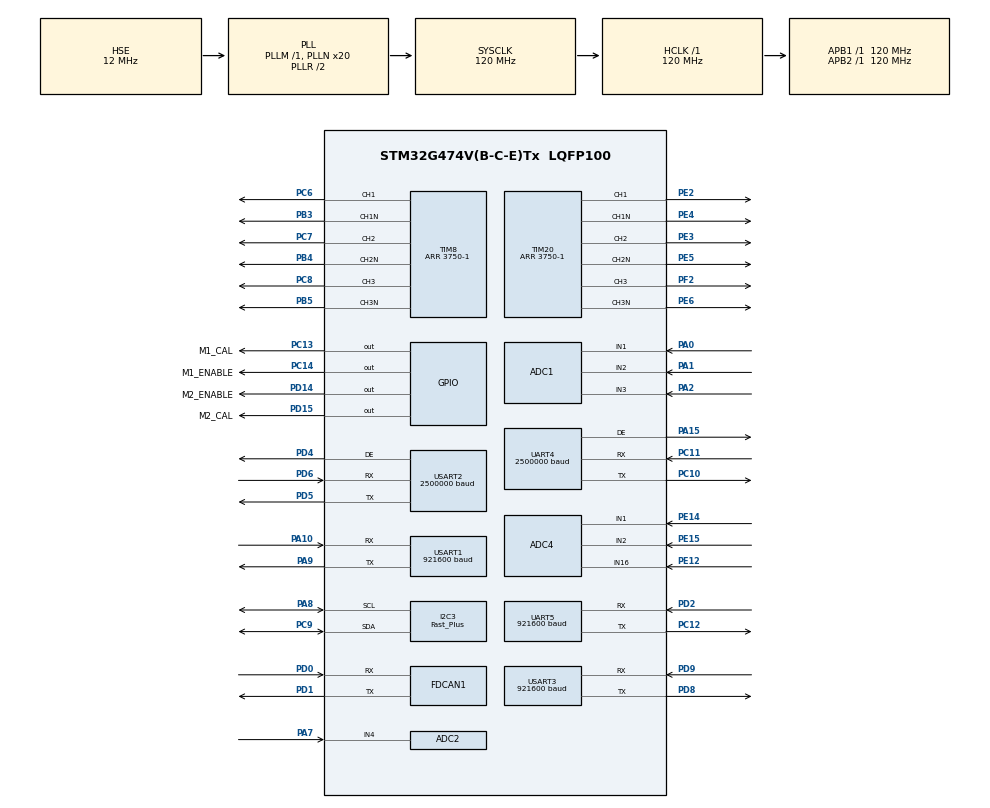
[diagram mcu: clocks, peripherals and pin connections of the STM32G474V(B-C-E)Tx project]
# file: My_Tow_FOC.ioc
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ADC1.ClockPrescaler=ADC_CLOCK_SYNC_PCLK_DIV4
ADC1.EnableInjectedConversion=ENABLE
ADC1.EnableRegularConversion=DISABLE
ADC1.ExternalTrigInjecConv=ADC_EXTERNALTRIGINJEC_T20_TRGO2
ADC1.InjNumberOfConversion=3
ADC1.InjectedChannel-4\#ChannelInjectedConversion=ADC_CHANNEL_1
ADC1.InjectedChannel-5\#ChannelInjectedConversion=ADC_CHANNEL_2
ADC1.InjectedChannel-6\#ChannelInjectedConversion=ADC_CHANNEL_3
ADC1.InjectedOffsetNumber-4\#ChannelInjectedConversion=ADC_OFFSET_NONE
ADC1.InjectedOffsetNumber-5\#ChannelInjectedConversion=ADC_OFFSET_NONE
ADC1.InjectedOffsetNumber-6\#ChannelInjectedConversion=ADC_OFFSET_NONE
ADC1.InjectedRank-4\#ChannelInjectedConversion=1
ADC1.InjectedRank-5\#ChannelInjectedConversion=2
ADC1.InjectedRank-6\#ChannelInjectedConversion=3
ADC1.InjectedSamplingTime-4\#ChannelInjectedConversion=ADC_SAMPLETIME_12CYCLES_5
ADC1.InjectedSamplingTime-5\#ChannelInjectedConversion=ADC_SAMPLETIME_12CYCLES_5
ADC1.InjectedSamplingTime-6\#ChannelInjectedConversion=ADC_SAMPLETIME_12CYCLES_5
ADC1.Rank1_Channel=ADC_CHANNEL_1
ADC1.Rank2_Channel=ADC_CHANNEL_2
ADC1.Rank3_Channel=ADC_CHANNEL_3
ADC1.master=1
ADC2.Channel-2\#ChannelRegularConversion=ADC_CHANNEL_4
ADC2.ClockPrescaler=ADC_CLOCK_SYNC_PCLK_DIV4
ADC2.ContinuousConvMode=ENABLE
ADC2.NbrOfConversionFlag=1
ADC2.OffsetNumber-2\#ChannelRegularConversion=ADC_OFFSET_NONE
ADC2.Rank-2\#ChannelRegularConversion=1
ADC2.SamplingTime-2\#ChannelRegularConversion=ADC_SAMPLETIME_12CYCLES_5
ADC4.ClockPrescaler=ADC_CLOCK_SYNC_PCLK_DIV4
ADC4.EnableInjectedConversion=ENABLE
ADC4.EnableRegularConversion=DISABLE
ADC4.ExternalTrigInjecConv=ADC_EXTERNALTRIGINJEC_T8_TRGO2
ADC4.InjNumberOfConversion=3
ADC4.InjectedChannel-2\#ChannelInjectedConversion=ADC_CHANNEL_2
ADC4.InjectedChannel-3\#ChannelInjectedConversion=ADC_CHANNEL_1
ADC4.InjectedChannel-4\#ChannelInjectedConversion=ADC_CHANNEL_16
ADC4.InjectedOffsetNumber-2\#ChannelInjectedConversion=ADC_OFFSET_NONE
ADC4.InjectedOffsetNumber-3\#ChannelInjectedConversion=ADC_OFFSET_NONE
ADC4.InjectedOffsetNumber-4\#ChannelInjectedConversion=ADC_OFFSET_NONE
ADC4.InjectedRank-2\#ChannelInjectedConversion=1
ADC4.InjectedRank-3\#ChannelInjectedConversion=2
ADC4.InjectedRank-4\#ChannelInjectedConversion=3
ADC4.InjectedSamplingTime-2\#ChannelInjectedConversion=ADC_SAMPLETIME_12CYCLES_5
ADC4.InjectedSamplingTime-3\#ChannelInjectedConversion=ADC_SAMPLETIME_12CYCLES_5
ADC4.InjectedSamplingTime-4\#ChannelInjectedConversion=ADC_SAMPLETIME_12CYCLES_5
ADC4.Rank1_Channel=ADC_CHANNEL_2
ADC4.Rank2_Channel=ADC_CHANNEL_1
ADC4.Rank3_Channel=ADC_CHANNEL_16
Dma.Request0=USART1_RX
Dma.Request1=USART1_TX
Dma.Request2=USART3_RX
Dma.Request3=USART3_TX
Dma.Request4=USART2_RX
Dma.Request5=USART2_TX
Dma.Request6=UART4_RX
Dma.Request7=UART4_TX
Dma.UART4_RX.6.Direction=DMA_PERIPH_TO_MEMORY
Dma.UART4_RX.6.EventEnable=DISABLE
Dma.UART4_RX.6.Instance=DMA1_Channel7
Dma.UART4_RX.6.MemDataAlignment=DMA_MDATAALIGN_BYTE
Dma.UART4_RX.6.MemInc=DMA_MINC_ENABLE
Dma.UART4_RX.6.Mode=DMA_NORMAL
Dma.UART4_RX.6.PeriphDataAlignment=DMA_PDATAALIGN_BYTE
Dma.UART4_RX.6.PeriphInc=DMA_PINC_DISABLE
Dma.UART4_RX.6.Polarity=HAL_DMAMUX_REQ_GEN_RISING
Dma.UART4_RX.6.Priority=DMA_PRIORITY_LOW
Dma.UART4_RX.6.RequestNumber=1
Dma.UART4_RX.6.SignalID=NONE
Dma.UART4_RX.6.SyncEnable=DISABLE
Dma.UART4_RX.6.SyncPolarity=HAL_DMAMUX_SYNC_NO_EVENT
Dma.UART4_RX.6.SyncRequestNumber=1
Dma.UART4_RX.6.SyncSignalID=NONE
Dma.UART4_TX.7.Direction=DMA_MEMORY_TO_PERIPH
Dma.UART4_TX.7.EventEnable=DISABLE
Dma.UART4_TX.7.Instance=DMA1_Channel8
Dma.UART4_TX.7.MemDataAlignment=DMA_MDATAALIGN_BYTE
Dma.UART4_TX.7.MemInc=DMA_MINC_ENABLE
Dma.UART4_TX.7.Mode=DMA_NORMAL
Dma.UART4_TX.7.PeriphDataAlignment=DMA_PDATAALIGN_BYTE
Dma.UART4_TX.7.PeriphInc=DMA_PINC_DISABLE
Dma.UART4_TX.7.Polarity=HAL_DMAMUX_REQ_GEN_RISING
Dma.UART4_TX.7.Priority=DMA_PRIORITY_LOW
Dma.UART4_TX.7.RequestNumber=1
Dma.UART4_TX.7.SignalID=NONE
Dma.UART4_TX.7.SyncEnable=DISABLE
Dma.UART4_TX.7.SyncPolarity=HAL_DMAMUX_SYNC_NO_EVENT
Dma.UART4_TX.7.SyncRequestNumber=1
Dma.UART4_TX.7.SyncSignalID=NONE
Dma.USART1_RX.0.Direction=DMA_PERIPH_TO_MEMORY
Dma.USART1_RX.0.EventEnable=DISABLE
Dma.USART1_RX.0.Instance=DMA1_Channel1
Dma.USART1_RX.0.MemDataAlignment=DMA_MDATAALIGN_BYTE
Dma.USART1_RX.0.MemInc=DMA_MINC_ENABLE
Dma.USART1_RX.0.Mode=DMA_NORMAL
Dma.USART1_RX.0.PeriphDataAlignment=DMA_PDATAALIGN_BYTE
Dma.USART1_RX.0.PeriphInc=DMA_PINC_DISABLE
Dma.USART1_RX.0.Polarity=HAL_DMAMUX_REQ_GEN_RISING
Dma.USART1_RX.0.Priority=DMA_PRIORITY_LOW
Dma.USART1_RX.0.RequestNumber=1
Dma.USART1_RX.0.SignalID=NONE
Dma.USART1_RX.0.SyncEnable=DISABLE
Dma.USART1_RX.0.SyncPolarity=HAL_DMAMUX_SYNC_NO_EVENT
Dma.USART1_RX.0.SyncRequestNumber=1
Dma.USART1_RX.0.SyncSignalID=NONE
Dma.USART1_TX.1.Direction=DMA_MEMORY_TO_PERIPH
Dma.USART1_TX.1.EventEnable=DISABLE
Dma.USART1_TX.1.Instance=DMA1_Channel2
Dma.USART1_TX.1.MemDataAlignment=DMA_MDATAALIGN_BYTE
Dma.USART1_TX.1.MemInc=DMA_MINC_ENABLE
Dma.USART1_TX.1.Mode=DMA_NORMAL
Dma.USART1_TX.1.PeriphDataAlignment=DMA_PDATAALIGN_BYTE
Dma.USART1_TX.1.PeriphInc=DMA_PINC_DISABLE
Dma.USART1_TX.1.Polarity=HAL_DMAMUX_REQ_GEN_RISING
Dma.USART1_TX.1.Priority=DMA_PRIORITY_LOW
Dma.USART1_TX.1.RequestNumber=1
Dma.USART1_TX.1.SignalID=NONE
Dma.USART1_TX.1.SyncEnable=DISABLE
Dma.USART1_TX.1.SyncPolarity=HAL_DMAMUX_SYNC_NO_EVENT
Dma.USART1_TX.1.SyncRequestNumber=1
Dma.USART1_TX.1.SyncSignalID=NONE
Dma.USART2_RX.4.Direction=DMA_PERIPH_TO_MEMORY
Dma.USART2_RX.4.EventEnable=DISABLE
Dma.USART2_RX.4.Instance=DMA1_Channel5
Dma.USART2_RX.4.MemDataAlignment=DMA_MDATAALIGN_BYTE
Dma.USART2_RX.4.MemInc=DMA_MINC_ENABLE
Dma.USART2_RX.4.Mode=DMA_NORMAL
Dma.USART2_RX.4.PeriphDataAlignment=DMA_PDATAALIGN_BYTE
Dma.USART2_RX.4.PeriphInc=DMA_PINC_DISABLE
Dma.USART2_RX.4.Polarity=HAL_DMAMUX_REQ_GEN_RISING
Dma.USART2_RX.4.Priority=DMA_PRIORITY_LOW
Dma.USART2_RX.4.RequestNumber=1
Dma.USART2_RX.4.SignalID=NONE
Dma.USART2_RX.4.SyncEnable=DISABLE
Dma.USART2_RX.4.SyncPolarity=HAL_DMAMUX_SYNC_NO_EVENT
Dma.USART2_RX.4.SyncRequestNumber=1
Dma.USART2_RX.4.SyncSignalID=NONE
Dma.USART2_TX.5.Direction=DMA_MEMORY_TO_PERIPH
Dma.USART2_TX.5.EventEnable=DISABLE
Dma.USART2_TX.5.Instance=DMA1_Channel6
Dma.USART2_TX.5.MemDataAlignment=DMA_MDATAALIGN_BYTE
Dma.USART2_TX.5.MemInc=DMA_MINC_ENABLE
Dma.USART2_TX.5.Mode=DMA_NORMAL
Dma.USART2_TX.5.PeriphDataAlignment=DMA_PDATAALIGN_BYTE
Dma.USART2_TX.5.PeriphInc=DMA_PINC_DISABLE
Dma.USART2_TX.5.Polarity=HAL_DMAMUX_REQ_GEN_RISING
Dma.USART2_TX.5.Priority=DMA_PRIORITY_LOW
Dma.USART2_TX.5.RequestNumber=1
Dma.USART2_TX.5.SignalID=NONE
Dma.USART2_TX.5.SyncEnable=DISABLE
Dma.USART2_TX.5.SyncPolarity=HAL_DMAMUX_SYNC_NO_EVENT
Dma.USART2_TX.5.SyncRequestNumber=1
Dma.USART2_TX.5.SyncSignalID=NONE
Dma.USART3_RX.2.Direction=DMA_PERIPH_TO_MEMORY
Dma.USART3_RX.2.EventEnable=DISABLE
Dma.USART3_RX.2.Instance=DMA1_Channel3
Dma.USART3_RX.2.MemDataAlignment=DMA_MDATAALIGN_BYTE
Dma.USART3_RX.2.MemInc=DMA_MINC_ENABLE
Dma.USART3_RX.2.Mode=DMA_NORMAL
Dma.USART3_RX.2.PeriphDataAlignment=DMA_PDATAALIGN_BYTE
Dma.USART3_RX.2.PeriphInc=DMA_PINC_DISABLE
Dma.USART3_RX.2.Polarity=HAL_DMAMUX_REQ_GEN_RISING
Dma.USART3_RX.2.Priority=DMA_PRIORITY_LOW
Dma.USART3_RX.2.RequestNumber=1
Dma.USART3_RX.2.SignalID=NONE
Dma.USART3_RX.2.SyncEnable=DISABLE
Dma.USART3_RX.2.SyncPolarity=HAL_DMAMUX_SYNC_NO_EVENT
Dma.USART3_RX.2.SyncRequestNumber=1
Dma.USART3_RX.2.SyncSignalID=NONE
Dma.USART3_TX.3.Direction=DMA_MEMORY_TO_PERIPH
Dma.USART3_TX.3.EventEnable=DISABLE
Dma.USART3_TX.3.Instance=DMA1_Channel4
Dma.USART3_TX.3.MemDataAlignment=DMA_MDATAALIGN_BYTE
Dma.USART3_TX.3.MemInc=DMA_MINC_ENABLE
Dma.USART3_TX.3.Mode=DMA_NORMAL
Dma.USART3_TX.3.PeriphDataAlignment=DMA_PDATAALIGN_BYTE
Dma.USART3_TX.3.PeriphInc=DMA_PINC_DISABLE
Dma.USART3_TX.3.Polarity=HAL_DMAMUX_REQ_GEN_RISING
Dma.USART3_TX.3.Priority=DMA_PRIORITY_LOW
Dma.USART3_TX.3.RequestNumber=1
Dma.USART3_TX.3.SignalID=NONE
Dma.USART3_TX.3.SyncEnable=DISABLE
Dma.USART3_TX.3.SyncPolarity=HAL_DMAMUX_SYNC_NO_EVENT
Dma.USART3_TX.3.SyncRequestNumber=1
Dma.USART3_TX.3.SyncSignalID=NONE
FDCAN1.CalculateBaudRateNominal=1000000
FDCAN1.CalculateTimeBitNominal=1000
FDCAN1.CalculateTimeQuantumNominal=50.0
FDCAN1.ClockDivider=FDCAN_CLOCK_DIV1
FDCAN1.NominalPrescaler=6
FDCAN1.NominalTimeSeg1=15
FDCAN1.NominalTimeSeg2=4
FREERTOS.Tasks01=defaultTask,24,128,StartDefaultTask,Default,NULL,Dynamic,NULL,NULL
FREERTOS.configTOTAL_HEAP_SIZE=80000
I2C3.I2C_Speed_Mode=I2C_Fast_Plus
I2C3.Timing=0x10820B1B
Mcu.Family=STM32G4
Mcu.Name=STM32G474V(B-C-E)Tx
Mcu.Package=LQFP100
NVIC.DMA1_Channel1_IRQn=true\:5\:0\:false\:false\:true\:true\:false\:true\:true
NVIC.DMA1_Channel2_IRQn=true\:5\:0\:false\:false\:true\:true\:false\:true\:true
NVIC.DMA1_Channel3_IRQn=true\:5\:0\:false\:false\:true\:true\:false\:true\:true
NVIC.DMA1_Channel4_IRQn=true\:5\:0\:false\:false\:true\:true\:false\:true\:true
NVIC.DMA1_Channel5_IRQn=true\:5\:0\:false\:false\:true\:true\:false\:true\:true
NVIC.DMA1_Channel6_IRQn=true\:5\:0\:false\:false\:true\:true\:false\:true\:true
NVIC.DMA1_Channel7_IRQn=true\:5\:0\:false\:false\:true\:true\:false\:true\:true
NVIC.DMA1_Channel8_IRQn=true\:5\:0\:false\:false\:true\:true\:false\:true\:true
NVIC.I2C3_ER_IRQn=true\:5\:0\:false\:false\:true\:true\:true\:true\:true
NVIC.I2C3_EV_IRQn=true\:5\:0\:false\:false\:true\:true\:true\:true\:true
NVIC.PriorityGroup=NVIC_PRIORITYGROUP_4
NVIC.TIM1_TRG_COM_TIM17_IRQn=true\:15\:0\:false\:false\:true\:false\:false\:true\:true
NVIC.TIM20_BRK_IRQn=true\:5\:0\:false\:false\:true\:true\:true\:true\:true
NVIC.TIM20_CC_IRQn=true\:5\:0\:false\:false\:true\:true\:true\:true\:true
NVIC.TIM20_TRG_COM_IRQn=true\:5\:0\:false\:false\:true\:true\:true\:true\:true
NVIC.TIM20_UP_IRQn=true\:5\:0\:false\:false\:true\:true\:true\:true\:true
NVIC.TIM8_BRK_IRQn=true\:5\:0\:false\:false\:true\:true\:true\:true\:true
NVIC.TIM8_CC_IRQn=true\:5\:0\:false\:false\:true\:true\:true\:true\:true
NVIC.TIM8_TRG_COM_IRQn=true\:5\:0\:false\:false\:true\:true\:true\:true\:true
NVIC.TIM8_UP_IRQn=true\:5\:0\:false\:false\:true\:true\:true\:true\:true
NVIC.TimeBase=TIM1_TRG_COM_TIM17_IRQn
NVIC.TimeBaseIP=TIM17
NVIC.UART4_IRQn=true\:5\:0\:false\:false\:true\:true\:true\:true\:true
NVIC.USART1_IRQn=true\:5\:0\:false\:false\:true\:true\:false\:true\:true
NVIC.USART2_IRQn=true\:5\:0\:false\:false\:true\:true\:true\:true\:true
NVIC.USART3_IRQn=true\:5\:0\:false\:false\:true\:true\:false\:true\:true
PA0.Mode=IN1-Single-Ended
PA0.Signal=ADC1_IN1
PA1.Mode=IN2-Single-Ended
PA1.Signal=ADC1_IN2
PA10.Mode=Asynchronous
PA10.Signal=USART1_RX
PA13.Mode=Serial_Wire
PA13.Signal=SYS_JTMS-SWDIO
PA14.Mode=Serial_Wire
PA14.Signal=SYS_JTCK-SWCLK
PA15.Mode=Hardware Flow Control (RS485)
PA15.Signal=UART4_DE
PA2.Mode=IN3-Single-Ended
PA2.Signal=ADC1_IN3
PA7.Mode=IN4-Single-Ended
PA7.Signal=ADC2_IN4
PA8.Mode=I2C
PA8.Signal=I2C3_SCL
PA9.Mode=Asynchronous
PA9.Signal=USART1_TX
PB3.Mode=PWM Generation1 CH1 CH1N
PB3.Signal=TIM8_CH1N
PB4.Mode=PWM Generation2 CH2 CH2N
PB4.Signal=TIM8_CH2N
PB5.Mode=PWM Generation3 CH3 CH3N
PB5.Signal=TIM8_CH3N
PC10.Mode=Asynchronous
PC10.Signal=UART4_TX
PC11.Mode=Asynchronous
PC11.Signal=UART4_RX
PC12.Mode=Asynchronous
PC12.Signal=UART5_TX
PC13.GPIO_Label=M1_CAL
PC13.GPIO_ModeDefaultOutputPP=GPIO_MODE_OUTPUT_PP
PC13.GPIO_PuPd=GPIO_PULLDOWN
PC13.GPIO_Speed=GPIO_SPEED_FREQ_LOW
PC13.PinState=GPIO_PIN_RESET
PC13.Signal=GPIO_Output
PC14-OSC32_IN.GPIO_Label=M1_ENABLE
PC14-OSC32_IN.GPIO_PuPd=GPIO_PULLUP
PC14-OSC32_IN.PinState=GPIO_PIN_SET
PC14-OSC32_IN.Signal=GPIO_Output
PC6.Signal=S_TIM8_CH1
PC7.Signal=S_TIM8_CH2
PC8.Signal=S_TIM8_CH3
PC9.Mode=I2C
PC9.Signal=I2C3_SDA
PD0.Mode=FDCAN_Activate
PD0.Signal=FDCAN1_RX
PD1.Mode=FDCAN_Activate
PD1.Signal=FDCAN1_TX
PD14.GPIO_Label=M2_ENABLE
PD14.GPIO_PuPd=GPIO_PULLUP
PD14.PinState=GPIO_PIN_SET
PD14.Signal=GPIO_Output
PD15.GPIO_Label=M2_CAL
PD15.GPIO_ModeDefaultOutputPP=GPIO_MODE_OUTPUT_PP
PD15.GPIO_PuPd=GPIO_PULLDOWN
PD15.GPIO_Speed=GPIO_SPEED_FREQ_LOW
PD15.PinState=GPIO_PIN_RESET
PD15.Signal=GPIO_Output
PD2.Mode=Asynchronous
PD2.Signal=UART5_RX
PD4.Mode=Hardware Flow Control (RS485)
PD4.Signal=USART2_DE
PD5.Mode=Asynchronous
PD5.Signal=USART2_TX
PD6.Mode=Asynchronous
PD6.Signal=USART2_RX
PD8.Mode=Asynchronous
PD8.Signal=USART3_TX
PD9.Mode=Asynchronous
PD9.Signal=USART3_RX
PE12.Mode=IN16-Single-Ended
PE12.Signal=ADC4_IN16
PE14.Mode=IN1-Single-Ended
PE14.Signal=ADC4_IN1
PE15.Mode=IN2-Single-Ended
PE15.Signal=ADC4_IN2
PE2.Signal=S_TIM20_CH1
PE3.Signal=S_TIM20_CH2
PE4.Mode=PWM Generation1 CH1 CH1N
PE4.Signal=TIM20_CH1N
PE5.Mode=PWM Generation2 CH2 CH2N
PE5.Signal=TIM20_CH2N
PE6.Mode=PWM Generation3 CH3 CH3N
PE6.Signal=TIM20_CH3N
PF0-OSC_IN.Mode=HSE-External-Oscillator
PF0-OSC_IN.Signal=RCC_OSC_IN
PF1-OSC_OUT.Mode=HSE-External-Oscillator
PF1-OSC_OUT.Signal=RCC_OSC_OUT
PF2.Signal=S_TIM20_CH3
ProjectManager.HeapSize=0xA00
ProjectManager.StackSize=0x800
ProjectManager.TargetToolchain=Makefile
RCC.ADC12Freq_Value=120000000
RCC.ADC345Freq_Value=120000000
RCC.AHBFreq_Value=120000000
RCC.APB1Freq_Value=120000000
RCC.APB1TimFreq_Value=120000000
RCC.APB2Freq_Value=120000000
RCC.APB2TimFreq_Value=120000000
RCC.CortexFreq_Value=120000000
RCC.EXTERNAL_CLOCK_VALUE=12288000
RCC.HCLKFreq_Value=120000000
RCC.HSE_VALUE=12000000
RCC.HSI48_VALUE=48000000
RCC.HSI_VALUE=16000000
RCC.LSE_VALUE=32768
RCC.PLLN=20
RCC.PLLSourceVirtual=RCC_PLLSOURCE_HSE
RCC.SYSCLKFreq_VALUE=120000000
RCC.SYSCLKSource=RCC_SYSCLKSOURCE_PLLCLK
RCC.USBFreq_Value=120000000
RCC.VCOOutputFreq_Value=240000000
SH.S_TIM20_CH1.0=TIM20_CH1,PWM Generation1 CH1 CH1N
SH.S_TIM20_CH2.0=TIM20_CH2,PWM Generation2 CH2 CH2N
SH.S_TIM20_CH3.0=TIM20_CH3,PWM Generation3 CH3 CH3N
SH.S_TIM8_CH1.0=TIM8_CH1,PWM Generation1 CH1 CH1N
SH.S_TIM8_CH2.0=TIM8_CH2,PWM Generation2 CH2 CH2N
SH.S_TIM8_CH3.0=TIM8_CH3,PWM Generation3 CH3 CH3N
TIM20.AutoReloadPreload=TIM_AUTORELOAD_PRELOAD_ENABLE
TIM20.Channel-PWM\ Generation1\ CH1\ CH1N=TIM_CHANNEL_1
TIM20.Channel-PWM\ Generation2\ CH2\ CH2N=TIM_CHANNEL_2
TIM20.Channel-PWM\ Generation3\ CH3\ CH3N=TIM_CHANNEL_3
TIM20.Channel-PWM\ Generation4\ No\ Output=TIM_CHANNEL_4
TIM20.Channel-PWM\ Generation5\ No\ Output=TIM_CHANNEL_5
TIM20.CounterMode=TIM_COUNTERMODE_CENTERALIGNED2
TIM20.DeadTime=100
TIM20.PeriodNoDither=3750-1
TIM20.TIM_MasterOutputTrigger2=TIM_TRGO2_OC5REF
TIM5.AutoReloadPreload=TIM_AUTORELOAD_PRELOAD_ENABLE
TIM5.Prescaler=120-1
TIM8.AutoReloadPreload=TIM_AUTORELOAD_PRELOAD_ENABLE
TIM8.Channel-PWM\ Generation1\ CH1\ CH1N=TIM_CHANNEL_1
TIM8.Channel-PWM\ Generation2\ CH2\ CH2N=TIM_CHANNEL_2
TIM8.Channel-PWM\ Generation3\ CH3\ CH3N=TIM_CHANNEL_3
TIM8.Channel-PWM\ Generation4\ No\ Output=TIM_CHANNEL_4
TIM8.Channel-PWM\ Generation5\ No\ Output=TIM_CHANNEL_5
TIM8.CounterMode=TIM_COUNTERMODE_CENTERALIGNED2
TIM8.DeadTime=100
TIM8.PeriodNoDither=3750-1
TIM8.TIM_MasterOutputTrigger2=TIM_TRGO2_OC5REF
UART4.BaudRate=2500000
UART5.BaudRate=921600
USART1.BaudRate=921600
USART1.VirtualMode-Asynchronous=VM_ASYNC
USART2.BaudRate=2500000
USART2.VirtualMode-Asynchronous=VM_ASYNC
USART2.VirtualMode-Hardware\ Flow\ Control\ (RS485)=VM_ASYNC
USART3.BaudRate=921600
USART3.VirtualMode-Asynchronous=VM_ASYNC
VP_FREERTOS_VS_CMSIS_V2.Mode=CMSIS_V2
VP_SYS_VS_DBSignals.Mode=DisableDeadBatterySignals
VP_SYS_VS_tim17.Mode=TIM17
VP_TIM20_VS_ClockSourceINT.Mode=Internal
VP_TIM20_VS_no_output4.Mode=PWM Generation4 No Output
VP_TIM20_VS_no_output5.Mode=PWM Generation5 No Output
VP_TIM5_VS_ClockSourceINT.Mode=Internal
VP_TIM8_VS_ClockSourceINT.Mode=Internal
VP_TIM8_VS_no_output4.Mode=PWM Generation4 No Output
VP_TIM8_VS_no_output5.Mode=PWM Generation5 No Output
board=custom

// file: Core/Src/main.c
/* USER CODE BEGIN Header */
/**
  ******************************************************************************
  * @file           : main.c
  * @brief          : Main program body
  ******************************************************************************
  * @attention
  *
  * Copyright (c) 2026 STMicroelectronics.
  * All rights reserved.
  *
  * This software is licensed under terms that can be found in the LICENSE file
  * in the root directory of this software component.
  * If no LICENSE file comes with this software, it is provided AS-IS.
  *
  ******************************************************************************
  */
/* USER CODE END Header */
#include "main.h"
#include "cmsis_os.h"
#include "adc.h"
#include "dma.h"
#include "fdcan.h"
#include "i2c.h"
#include "tim.h"
#include "usart.h"
#include "gpio.h"

void SystemClock_Config(void);
void MX_FREERTOS_Init(void);

int main(void)
{

  /* MCU Configuration--------------------------------------------------------*/

  /* Reset of all peripherals, Initializes the Flash interface and the Systick. */
  HAL_Init();

  /* Configure the system clock */
  SystemClock_Config();

  /* Initialize all configured peripherals */
  MX_GPIO_Init();
  MX_DMA_Init();
  MX_USART1_UART_Init();
  MX_USART3_UART_Init();
  MX_ADC1_Init();
  MX_TIM20_Init();
  MX_TIM8_Init();
  MX_ADC2_Init();
  MX_ADC4_Init();
  MX_FDCAN1_Init();
  MX_UART4_Init();
  MX_UART5_Init();
  MX_USART2_UART_Init();
  MX_TIM5_Init();
  MX_I2C3_Init();

  /* Init scheduler */
  osKernelInitialize();  /* Call init function for freertos objects (in cmsis_os2.c) */
  MX_FREERTOS_Init();

  /* Start scheduler */
  osKernelStart();

  /* We should never get here as control is now taken by the scheduler */

  /* Infinite loop */
  while (1)
  {

  }
}

void SystemClock_Config(void)
{
  RCC_OscInitTypeDef RCC_OscInitStruct = {0};
  RCC_ClkInitTypeDef RCC_ClkInitStruct = {0};

  /** Configure the main internal regulator output voltage
  */
  HAL_PWREx_ControlVoltageScaling(PWR_REGULATOR_VOLTAGE_SCALE1);

  /** Initializes the RCC Oscillators according to the specified parameters
  * in the RCC_OscInitTypeDef structure.
  */
  RCC_OscInitStruct.OscillatorType = RCC_OSCILLATORTYPE_HSE;
  RCC_OscInitStruct.HSEState = RCC_HSE_ON;
  RCC_OscInitStruct.PLL.PLLState = RCC_PLL_ON;
  RCC_OscInitStruct.PLL.PLLSource = RCC_PLLSOURCE_HSE;
  RCC_OscInitStruct.PLL.PLLM = RCC_PLLM_DIV1;
  RCC_OscInitStruct.PLL.PLLN = 20;
  RCC_OscInitStruct.PLL.PLLP = RCC_PLLP_DIV2;
  RCC_OscInitStruct.PLL.PLLQ = RCC_PLLQ_DIV2;
  RCC_OscInitStruct.PLL.PLLR = RCC_PLLR_DIV2;
  if (HAL_RCC_OscConfig(&RCC_OscInitStruct) != HAL_OK)
  {
    Error_Handler();
  }

  /** Initializes the CPU, AHB and APB buses clocks
  */
  RCC_ClkInitStruct.ClockType = RCC_CLOCKTYPE_HCLK|RCC_CLOCKTYPE_SYSCLK
                              |RCC_CLOCKTYPE_PCLK1|RCC_CLOCKTYPE_PCLK2;
  RCC_ClkInitStruct.SYSCLKSource = RCC_SYSCLKSOURCE_PLLCLK;
  RCC_ClkInitStruct.AHBCLKDivider = RCC_SYSCLK_DIV1;
  RCC_ClkInitStruct.APB1CLKDivider = RCC_HCLK_DIV1;
  RCC_ClkInitStruct.APB2CLKDivider = RCC_HCLK_DIV1;

  if (HAL_RCC_ClockConfig(&RCC_ClkInitStruct, FLASH_LATENCY_3) != HAL_OK)
  {
    Error_Handler();
  }
}

void HAL_TIM_PeriodElapsedCallback(TIM_HandleTypeDef *htim)
{
  if (htim->Instance == TIM17)
  {
    HAL_IncTick();
  }
}

void Error_Handler(void)
{
  __disable_irq();
  while (1)
  {
  }
}

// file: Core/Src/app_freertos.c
/* USER CODE BEGIN Header */
/**
  ******************************************************************************
  * File Name          : app_freertos.c
  * Description        : Code for freertos applications
  ******************************************************************************
  * @attention
  *
  * Copyright (c) 2026 STMicroelectronics.
  * All rights reserved.
  *
  * This software is licensed under terms that can be found in the LICENSE file
  * in the root directory of this software component.
  * If no LICENSE file comes with this software, it is provided AS-IS.
  *
  ******************************************************************************
  */
/* USER CODE END Header */

#include "FreeRTOS.h"
#include "task.h"
#include "main.h"
#include "cmsis_os.h"

/* Definitions for defaultTask */
osThreadId_t defaultTaskHandle;
const osThreadAttr_t defaultTask_attributes = {
  .name = "defaultTask",
  .priority = (osPriority_t) osPriorityNormal,
  .stack_size = 128 * 4
};

void StartDefaultTask(void *argument);

void MX_FREERTOS_Init(void); /* (MISRA C 2004 rule 8.1) */

void MX_FREERTOS_Init(void) {
  /* USER CODE BEGIN Init */
  extern void MC_ScheduleStart(void);
  MC_ScheduleStart();
  return;
  /* USER CODE END Init */

  /* Create the thread(s) */
  /* creation of defaultTask */
  defaultTaskHandle = osThreadNew(StartDefaultTask, NULL, &defaultTask_attributes);

}

void StartDefaultTask(void *argument)
{
  for(;;)
  {
    osDelay(1);
  }
}
